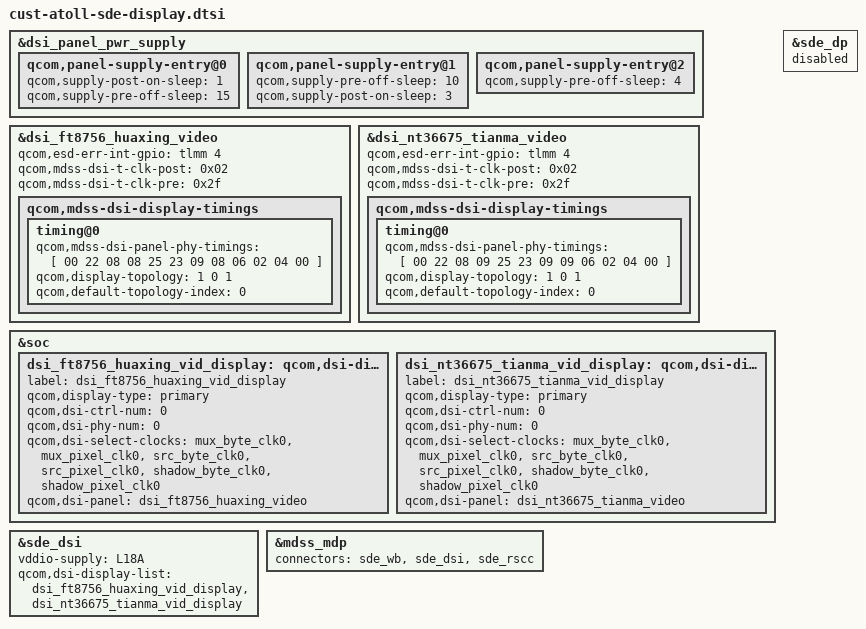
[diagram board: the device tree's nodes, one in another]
#include "dsi-panel-ft8756-huaxing-fhd-video.dtsi"
#include "dsi-panel-nt36675-tianma-fhd-video.dtsi"

&dsi_panel_pwr_supply {
	qcom,panel-supply-entry@0 {
		qcom,supply-post-on-sleep = <1>;
		qcom,supply-pre-off-sleep = <15>;
	};

	qcom,panel-supply-entry@1 {
		qcom,supply-pre-off-sleep = <10>;
		qcom,supply-post-on-sleep = <3>;
	};

	qcom,panel-supply-entry@2 {
		/delete-property/ qcom,supply-post-on-sleep;
		qcom,supply-pre-off-sleep = <4>;
	};
};

&dsi_ft8756_huaxing_video {
	qcom,esd-err-int-gpio = <&tlmm 4 0>;
	qcom,mdss-dsi-t-clk-post = <0x02>;
	qcom,mdss-dsi-t-clk-pre = <0x2f>;
	qcom,mdss-dsi-display-timings {
		timing@0{
			qcom,mdss-dsi-panel-phy-timings = [
				00 22 08 08 25 23 09
				08 06 02 04 00
			];
			qcom,display-topology = <1 0 1>;
			qcom,default-topology-index = <0>;
		};
	};
};

&dsi_nt36675_tianma_video {
	qcom,esd-err-int-gpio = <&tlmm 4 0>;
	qcom,mdss-dsi-t-clk-post = <0x02>;
	qcom,mdss-dsi-t-clk-pre = <0x2f>;
	qcom,mdss-dsi-display-timings {
		timing@0{
			qcom,mdss-dsi-panel-phy-timings = [
				00 22 08 09 25 23 09
				09 06 02 04 00
			];
			qcom,display-topology = <1 0 1>;
			qcom,default-topology-index = <0>;
		};
	};
};

&soc {
	dsi_ft8756_huaxing_vid_display: qcom,dsi-display@6 {
		label = "dsi_ft8756_huaxing_vid_display";
		qcom,display-type = "primary";
		qcom,dsi-ctrl-num = <0>;
		qcom,dsi-phy-num = <0>;
		qcom,dsi-select-clocks = "mux_byte_clk0", "mux_pixel_clk0",
			"src_byte_clk0", "src_pixel_clk0",
			"shadow_byte_clk0", "shadow_pixel_clk0";
		qcom,dsi-panel = <&dsi_ft8756_huaxing_video>;
	};

	dsi_nt36675_tianma_vid_display: qcom,dsi-display@7 {
		label = "dsi_nt36675_tianma_vid_display";
		qcom,display-type = "primary";
		qcom,dsi-ctrl-num = <0>;
		qcom,dsi-phy-num = <0>;
		qcom,dsi-select-clocks = "mux_byte_clk0", "mux_pixel_clk0",
			"src_byte_clk0", "src_pixel_clk0",
			"shadow_byte_clk0", "shadow_pixel_clk0";
		qcom,dsi-panel = <&dsi_nt36675_tianma_video>;
	};
};

&sde_dsi {
	/delete-property/ vdda-3p3-supply;

	vddio-supply = <&L18A>;
	qcom,dsi-display-list = <
		&dsi_ft8756_huaxing_vid_display
		&dsi_nt36675_tianma_vid_display
	>;
};

&sde_dp {
	status = "disabled";
};

&mdss_mdp {
	connectors = <&sde_wb &sde_dsi &sde_rscc>;
};
